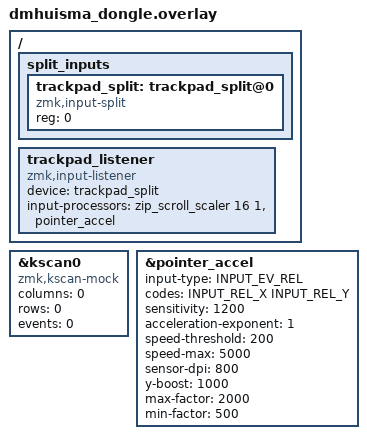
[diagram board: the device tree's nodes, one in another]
#include "dmhuisma.dtsi"
#include <behaviors.dtsi>
#include <input/processors.dtsi>
#include <dt-bindings/zmk/input_transform.h>
#include <zephyr/dt-bindings/input/input-event-codes.h>
#include <behaviors/input_gestures_accel.dtsi>

#define COLEMAK         0
#define QWERTY          1
#define GAME            2
#define RAISE           3
#define LOWER        	4

&kscan0 {
    compatible = "zmk,kscan-mock";
    columns = <0>;
    rows = <0>;
    events = <0>;
};

&pointer_accel {
    input-type = <INPUT_EV_REL>;
    codes = <INPUT_REL_X INPUT_REL_Y>;
    sensitivity = <1200>;
    acceleration-exponent = <1>;
    speed-threshold = <200>;
    speed-max = <5000>;
    sensor-dpi = <800>;

    y-boost = <1000>;
    max-factor = <2000>;
    min-factor = <500>;
};

/ {
    split_inputs {
        #address-cells = <1>;
        #size-cells = <0>;

        trackpad_split: trackpad_split@0 {
            compatible = "zmk,input-split";
            reg = <0>;
        };
    };

    trackpad_listener: trackpad_listener {
        compatible = "zmk,input-listener";
        status = "ok";
        device = <&trackpad_split>;

        input-processors = <&zip_scroll_scaler 16 1>, <&pointer_accel>;
    };
};
